# STM32G07x register map
File version: 1.3
CPU: CM0+ r0p0, little endian, no MPU, no FPU, 3 interrupt priority bits
Registers are 32-bit, read-write, reset 0x0 unless marked. A register's access mark holds for its fields unless they carry their own. Offsets are from the block's base; [hi:lo] are bit positions; {n}, {i} and the like mark numbered series.

## TIM14 — General purpose timers
Base 0x40002000
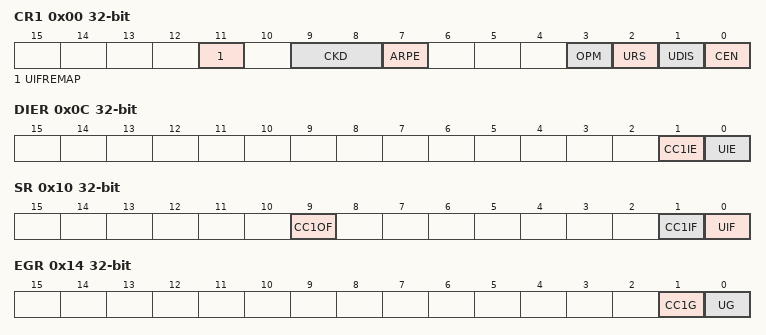
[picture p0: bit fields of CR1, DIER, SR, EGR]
0x00 CR1 — control register 1
  [11] UIFREMAP — UIF status bit remapping
  [9:8] CKD — Clock division
  [7] ARPE — Auto-reload preload enable
  [3] OPM — One-pulse mode
  [2] URS — Update request source
  [1] UDIS — Update disable
  [0] CEN — Counter enable
0x0C DIER — DMA/Interrupt enable register
  [1] CC1IE — Capture/Compare 1 interrupt enable
  [0] UIE — Update interrupt enable
0x10 SR — status register
  [9] CC1OF — Capture/Compare 1 overcapture flag
  [1] CC1IF — Capture/compare 1 interrupt flag
  [0] UIF — Update interrupt flag
0x14 EGR wo — event generation register
  [1] CC1G — Capture/compare 1 generation
  [0] UG — Update generation
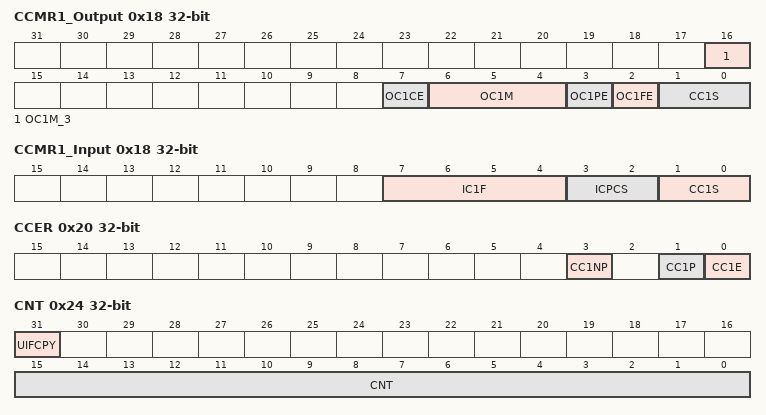
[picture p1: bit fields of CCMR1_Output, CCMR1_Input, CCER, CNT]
0x18 CCMR1_Output — capture/compare mode register 1 (output mode)
  [16] OC1M_3 — Output Compare 1 mode - bit 3
  [7] OC1CE
  [6:4] OC1M
  [3] OC1PE
  [2] OC1FE
  [1:0] CC1S
0x18 CCMR1_Input (alternate view of CCMR1_Output) — capture/compare mode register 1 (input mode)
  [7:4] IC1F — Input capture 1 filter
  [3:2] ICPCS — Input capture 1 prescaler
  [1:0] CC1S — Capture/Compare 1 selection
0x20 CCER — capture/compare enable register
  [3] CC1NP — Capture/Compare 1 output Polarity
  [1] CC1P — Capture/Compare 1 output Polarity
  [0] CC1E — Capture/Compare 1 output enable
0x24 CNT — counter
  [31] UIFCPY — UIF Copy
  [15:0] CNT — low counter value
0x28 PSC — prescaler
  [15:0] PSC — Prescaler value
0x2C ARR — auto-reload register
  [15:0] ARR — Low Auto-reload value
0x34 CCR1 — capture/compare register 1
  [15:0] CCR1 — Low Capture/Compare 1 value
0x68 TISEL — TIM timer input selection register
  [3:0] TISEL — TI1[0] to TI1[15] input selection

## TIM6 — Basic timers
Base 0x40001000
Same registers: TIM7 0x40001400
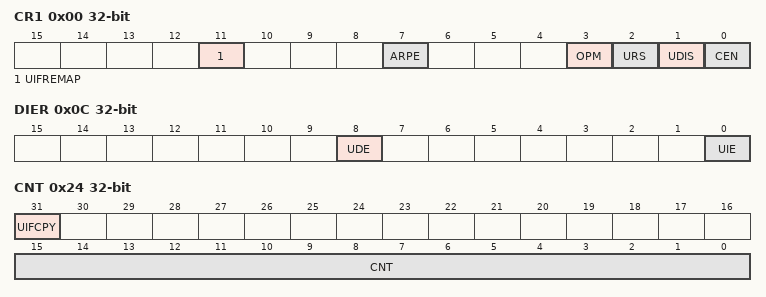
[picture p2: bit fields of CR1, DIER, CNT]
0x00 CR1 — control register 1
  [11] UIFREMAP — UIF status bit remapping
  [7] ARPE — Auto-reload preload enable
  [3] OPM — One-pulse mode
  [2] URS — Update request source
  [1] UDIS — Update disable
  [0] CEN — Counter enable
0x04 CR2 — control register 2
  [6:4] MMS — Master mode selection
0x0C DIER — DMA/Interrupt enable register
  [8] UDE — Update DMA request enable
  [0] UIE — Update interrupt enable
0x10 SR — status register
  [0] UIF — Update interrupt flag
0x14 EGR wo — event generation register
  [0] UG — Update generation
0x24 CNT — counter
  [31] UIFCPY — UIF Copy
  [15:0] CNT — Low counter value
0x28 PSC — prescaler
  [15:0] PSC — Prescaler value
0x2C ARR — auto-reload register
  [15:0] ARR — Low Auto-reload value

## NVIC — Nested Vectored Interrupt Controller
Base 0xE000E100
0x00 ISER — Interrupt Set Enable Register
  [31:0] SETENA
0x80 ICER — Interrupt Clear Enable Register
  [31:0] CLRENA
0x100 ISPR — Interrupt Set-Pending Register
  [31:0] SETPEND
0x180 ICPR — Interrupt Clear-Pending Register
  [31:0] CLRPEND
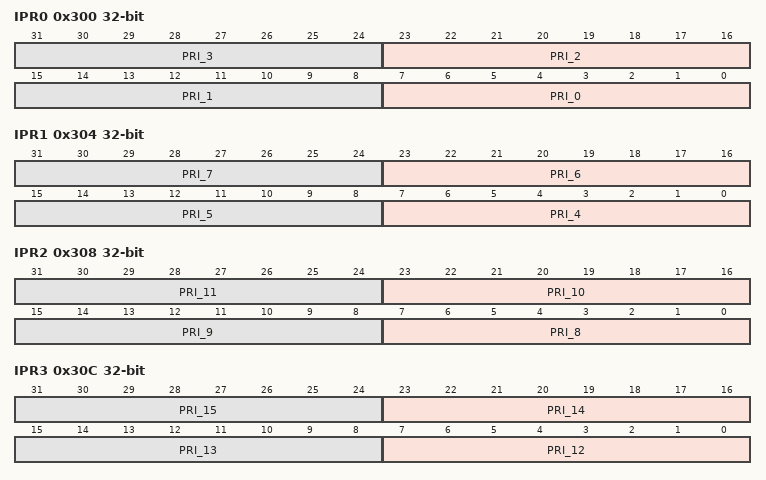
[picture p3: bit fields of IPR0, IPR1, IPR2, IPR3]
0x300 IPR0 — Interrupt Priority Register 0
  [8n+7:8n] PRI_{n} (n=0..3) — priority for interrupt {n}
0x304 IPR1 — Interrupt Priority Register 1
  [8n-25:8n-32] PRI_{n} (n=4..7) — priority for interrupt n
0x308 IPR2 — Interrupt Priority Register 2
  [8n-57:8n-64] PRI_{n} (n=8..11) — priority for interrupt n
0x30C IPR3 — Interrupt Priority Register 3
  [8n-89:8n-96] PRI_{n} (n=12..15) — priority for interrupt n
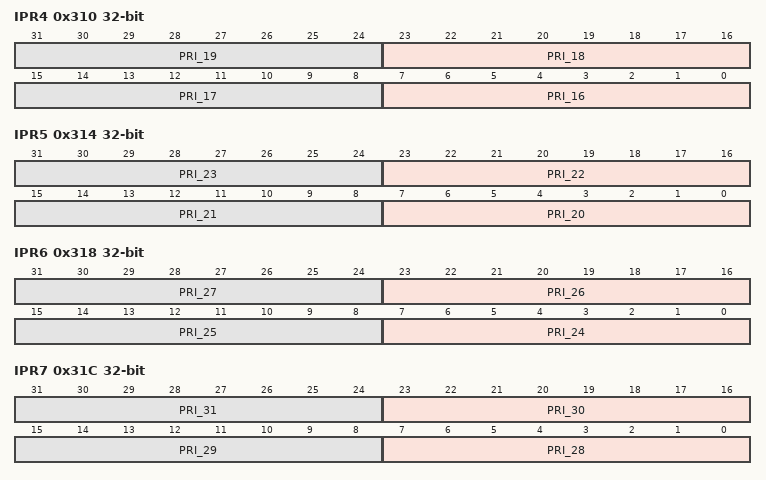
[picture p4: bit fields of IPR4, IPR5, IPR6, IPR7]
0x310 IPR4 — Interrupt Priority Register 4
  [8n-121:8n-128] PRI_{n} (n=16..19) — priority for interrupt n
0x314 IPR5 — Interrupt Priority Register 5
  [8n-153:8n-160] PRI_{n} (n=20..23) — priority for interrupt n
0x318 IPR6 — Interrupt Priority Register 6
  [8n-185:8n-192] PRI_{n} (n=24..27) — priority for interrupt n
0x31C IPR7 — Interrupt Priority Register 7
  [8n-217:8n-224] PRI_{n} (n=28..31) — priority for interrupt n

## MPU — Memory protection unit
Base 0xE000ED90
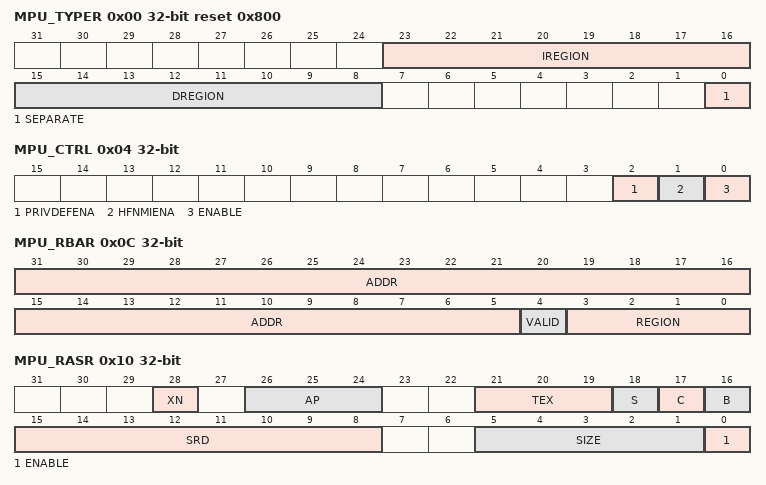
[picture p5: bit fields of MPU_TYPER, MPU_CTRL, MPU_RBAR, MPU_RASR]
0x00 MPU_TYPER ro reset 0x800 — MPU type register
  [23:16] IREGION — Number of MPU instruction regions
  [15:8] DREGION — Number of MPU data regions
  [0] SEPARATE — Separate flag
0x04 MPU_CTRL ro — MPU control register
  [2] PRIVDEFENA — Enable priviliged software access to default memory map
  [1] HFNMIENA — Enables the operation of MPU during hard fault
  [0] ENABLE — Enables the MPU
0x08 MPU_RNR — MPU region number register
  [7:0] REGION — MPU region
0x0C MPU_RBAR — MPU region base address register
  [31:5] ADDR — Region base address field
  [4] VALID — MPU region number valid
  [3:0] REGION — MPU region field
0x10 MPU_RASR — MPU region attribute and size register
  [28] XN — Instruction access disable bit
  [26:24] AP — Access permission
  [21:19] TEX — memory attribute
  [18] S — Shareable memory attribute
  [17] C — memory attribute
  [16] B — memory attribute
  [15:8] SRD — Subregion disable bits
  [5:1] SIZE — Size of the MPU protection region
  [0] ENABLE — Region enable bit.

## STK — SysTick timer
Base 0xE000E010
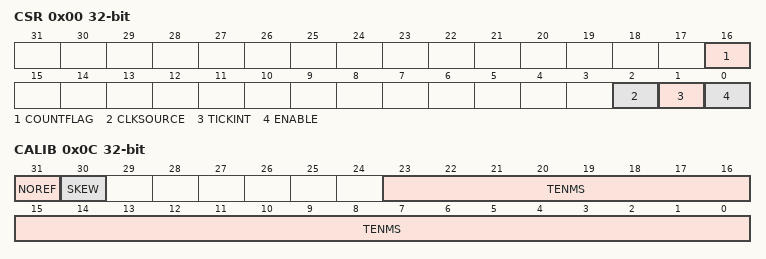
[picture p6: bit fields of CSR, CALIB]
0x00 CSR — SysTick control and status register
  [16] COUNTFLAG
  [2] CLKSOURCE — Clock source selection
  [1] TICKINT — SysTick exception request enable
  [0] ENABLE — Counter enable
0x04 RVR — SysTick reload value register
  [23:0] RELOAD — RELOAD value
0x08 CVR — SysTick current value register
  [23:0] CURRENT — Current counter value
0x0C CALIB — SysTick calibration value register
  [31] NOREF — NOREF flag. Reads as zero
  [30] SKEW — SKEW flag: Indicates whether the TENMS value is exact
  [23:0] TENMS — Calibration value

## SCB — System control block
Base 0xE000ED00
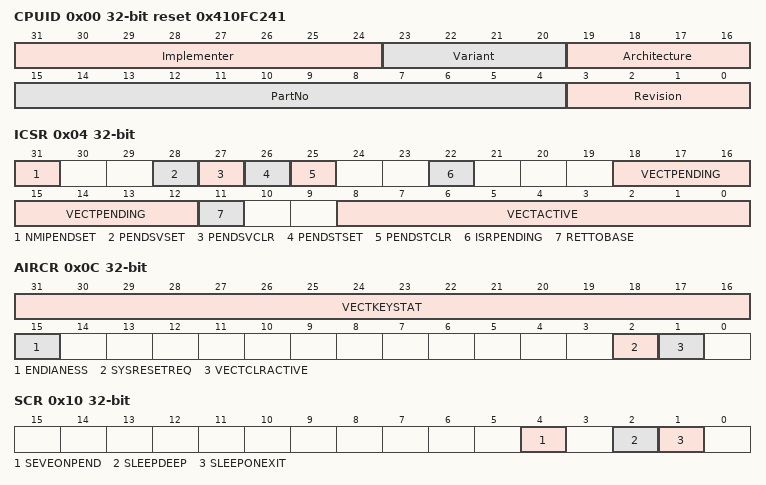
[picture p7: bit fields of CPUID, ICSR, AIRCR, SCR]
0x00 CPUID ro reset 0x410FC241 — CPUID base register
  [31:24] Implementer — Implementer code
  [23:20] Variant — Variant number
  [19:16] Architecture — Reads as 0xF
  [15:4] PartNo — Part number of the processor
  [3:0] Revision — Revision number
0x04 ICSR — Interrupt control and state register
  [31] NMIPENDSET — NMI set-pending bit.
  [28] PENDSVSET — PendSV set-pending bit
  [27] PENDSVCLR — PendSV clear-pending bit
  [26] PENDSTSET — SysTick exception set-pending bit
  [25] PENDSTCLR — SysTick exception clear-pending bit
  [22] ISRPENDING — Interrupt pending flag
  [18:12] VECTPENDING — Pending vector
  [11] RETTOBASE — Return to base level
  [8:0] VECTACTIVE — Active vector
0x08 VTOR — Vector table offset register
  [31:7] TBLOFF — Vector table base offset field
0x0C AIRCR — Application interrupt and reset control register
  [31:16] VECTKEYSTAT — Register key
  [15] ENDIANESS
  [2] SYSRESETREQ
  [1] VECTCLRACTIVE
0x10 SCR — System control register
  [4] SEVEONPEND — Send Event on Pending bit
  [2] SLEEPDEEP
  [1] SLEEPONEXIT
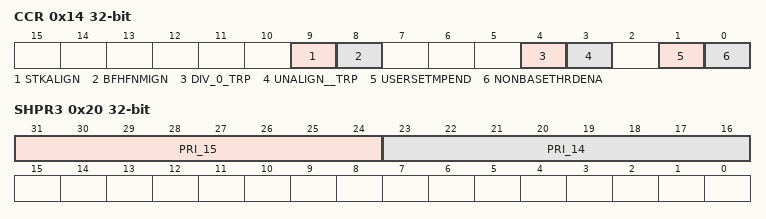
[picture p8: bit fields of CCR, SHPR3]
0x14 CCR — Configuration and control register
  [9] STKALIGN
  [8] BFHFNMIGN
  [4] DIV_0_TRP
  [3] UNALIGN__TRP
  [1] USERSETMPEND
  [0] NONBASETHRDENA — Configures how the processor enters Thread mode
0x1C SHPR2 — System handler priority registers
  [31:24] PRI_11 — Priority of system handler 11
0x20 SHPR3 — System handler priority registers
  [31:24] PRI_15 — Priority of system handler 15
  [23:16] PRI_14 — Priority of system handler 14
